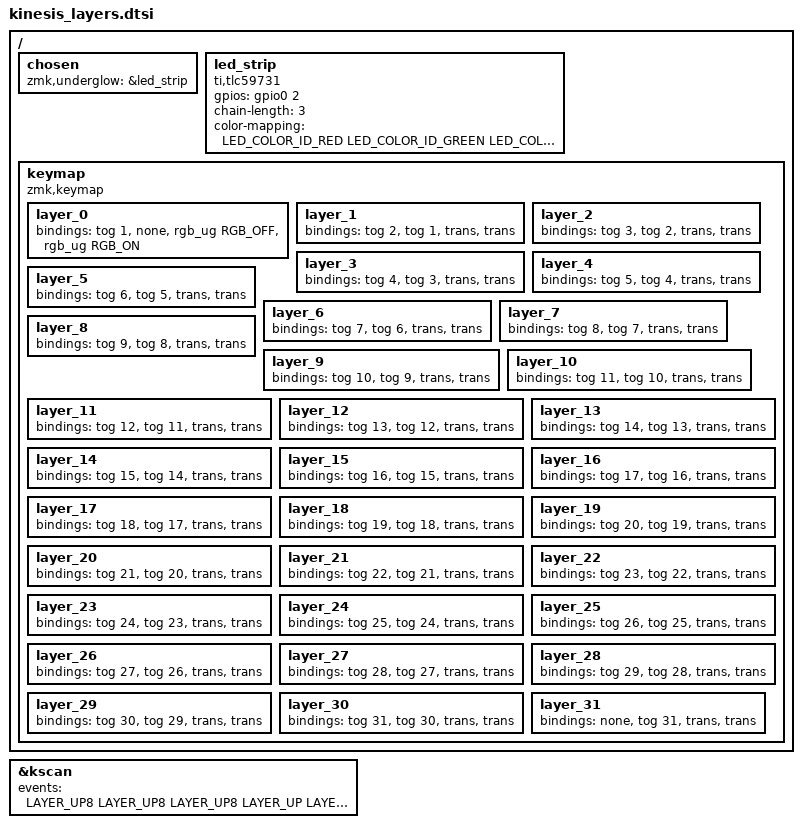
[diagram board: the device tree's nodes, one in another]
/*
 * Copyright (c) 2026 The ZMK Contributors
 *
 * SPDX-License-Identifier: MIT
 */

#include <dt-bindings/zmk/keys.h>
#include <behaviors.dtsi>
#include <dt-bindings/zmk/kscan_mock.h>
#include <dt-bindings/zmk/rgb.h>
#include <zephyr/dt-bindings/led/led.h>

#define LAYER_UP ZMK_MOCK_PRESS(0,0,10) ZMK_MOCK_RELEASE(0,0,10)
#define LAYER_DOWN ZMK_MOCK_PRESS(0,1,10) ZMK_MOCK_RELEASE(0,1,10)
#define LAYER_UP8 LAYER_UP LAYER_UP LAYER_UP LAYER_UP LAYER_UP LAYER_UP LAYER_UP LAYER_UP
#define LAYER_DOWN8 LAYER_DOWN LAYER_DOWN LAYER_DOWN LAYER_DOWN LAYER_DOWN LAYER_DOWN LAYER_DOWN LAYER_DOWN

/ {
    chosen {
        zmk,underglow = &led_strip;
    };

    // A real led_strip device on native_sim: bit-banged over the emulated GPIO controller.
    led_strip: led_strip {
        compatible = "ti,tlc59731";
        gpios = <&gpio0 2 GPIO_ACTIVE_HIGH>;
        chain-length = <3>;
        color-mapping = <LED_COLOR_ID_RED LED_COLOR_ID_GREEN LED_COLOR_ID_BLUE>;
    };

    // Layer n: &tog n+1 walks up, &tog n walks back down; layer 0 row 2 is RGB_OFF, RGB_ON.
    keymap {
        compatible = "zmk,keymap";
        layer_0 { bindings = <&tog 1 &none &rgb_ug RGB_OFF &rgb_ug RGB_ON>; };
        layer_1 { bindings = <&tog 2 &tog 1 &trans &trans>; };
        layer_2 { bindings = <&tog 3 &tog 2 &trans &trans>; };
        layer_3 { bindings = <&tog 4 &tog 3 &trans &trans>; };
        layer_4 { bindings = <&tog 5 &tog 4 &trans &trans>; };
        layer_5 { bindings = <&tog 6 &tog 5 &trans &trans>; };
        layer_6 { bindings = <&tog 7 &tog 6 &trans &trans>; };
        layer_7 { bindings = <&tog 8 &tog 7 &trans &trans>; };
        layer_8 { bindings = <&tog 9 &tog 8 &trans &trans>; };
        layer_9 { bindings = <&tog 10 &tog 9 &trans &trans>; };
        layer_10 { bindings = <&tog 11 &tog 10 &trans &trans>; };
        layer_11 { bindings = <&tog 12 &tog 11 &trans &trans>; };
        layer_12 { bindings = <&tog 13 &tog 12 &trans &trans>; };
        layer_13 { bindings = <&tog 14 &tog 13 &trans &trans>; };
        layer_14 { bindings = <&tog 15 &tog 14 &trans &trans>; };
        layer_15 { bindings = <&tog 16 &tog 15 &trans &trans>; };
        layer_16 { bindings = <&tog 17 &tog 16 &trans &trans>; };
        layer_17 { bindings = <&tog 18 &tog 17 &trans &trans>; };
        layer_18 { bindings = <&tog 19 &tog 18 &trans &trans>; };
        layer_19 { bindings = <&tog 20 &tog 19 &trans &trans>; };
        layer_20 { bindings = <&tog 21 &tog 20 &trans &trans>; };
        layer_21 { bindings = <&tog 22 &tog 21 &trans &trans>; };
        layer_22 { bindings = <&tog 23 &tog 22 &trans &trans>; };
        layer_23 { bindings = <&tog 24 &tog 23 &trans &trans>; };
        layer_24 { bindings = <&tog 25 &tog 24 &trans &trans>; };
        layer_25 { bindings = <&tog 26 &tog 25 &trans &trans>; };
        layer_26 { bindings = <&tog 27 &tog 26 &trans &trans>; };
        layer_27 { bindings = <&tog 28 &tog 27 &trans &trans>; };
        layer_28 { bindings = <&tog 29 &tog 28 &trans &trans>; };
        layer_29 { bindings = <&tog 30 &tog 29 &trans &trans>; };
        layer_30 { bindings = <&tog 31 &tog 30 &trans &trans>; };
        layer_31 { bindings = <&none &tog 31 &trans &trans>; };
    };
};

&kscan {
    events = <
        /* up through layers 1..31, down through 30..0, then RGB_OFF, RGB_ON */
        LAYER_UP8 LAYER_UP8 LAYER_UP8 LAYER_UP LAYER_UP LAYER_UP LAYER_UP LAYER_UP LAYER_UP LAYER_UP
        LAYER_DOWN8 LAYER_DOWN8 LAYER_DOWN8 LAYER_DOWN LAYER_DOWN LAYER_DOWN LAYER_DOWN LAYER_DOWN LAYER_DOWN LAYER_DOWN
        ZMK_MOCK_PRESS(1,0,10) ZMK_MOCK_RELEASE(1,0,10)
        ZMK_MOCK_PRESS(1,1,10) ZMK_MOCK_RELEASE(1,1,10)
    >;
};
